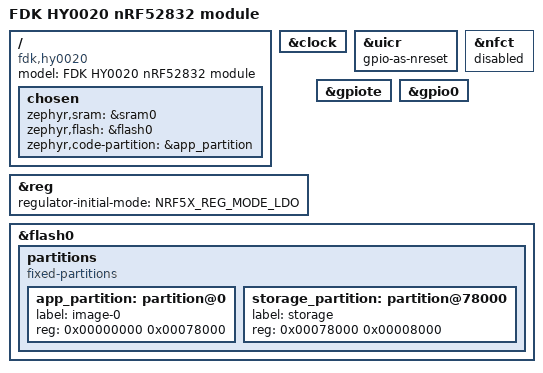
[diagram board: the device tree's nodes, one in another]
/dts-v1/;

#include <nordic/nrf52832_qfaa.dtsi>
#include <zephyr/dt-bindings/regulator/nrf5x.h>

/ {
    model = "FDK HY0020 nRF52832 module";
    compatible = "fdk,hy0020";

    chosen {
        zephyr,sram = &sram0;
        zephyr,flash = &flash0;
        zephyr,code-partition = &app_partition;
    };
};

/* HY0020 contains both the 32 MHz HFXO and 32.768 kHz LFXO crystals. */
&clock {
    status = "okay";
};

/* Use the internal LDO during initial board bring-up. */
&reg {
    regulator-initial-mode = <NRF5X_REG_MODE_LDO>;
};

/* P0.21 is wired as the active-low hardware reset input. */
&uicr {
    gpio-as-nreset;
};

/* P0.09/P0.10 are not used during initial bring-up. */
&nfct {
    status = "disabled";
};

&gpiote {
    status = "okay";
};

&gpio0 {
    status = "okay";
};

&flash0 {
    partitions {
        compatible = "fixed-partitions";
        #address-cells = <1>;
        #size-cells = <1>;

        /* Direct SWD image: firmware starts at address 0, with no bootloader. */
        app_partition: partition@0 {
            label = "image-0";
            reg = <0x00000000 0x00078000>;
        };

        /* Last 32 KiB is reserved for ZMK Bluetooth/settings storage. */
        storage_partition: partition@78000 {
            label = "storage";
            reg = <0x00078000 0x00008000>;
        };
    };
};
